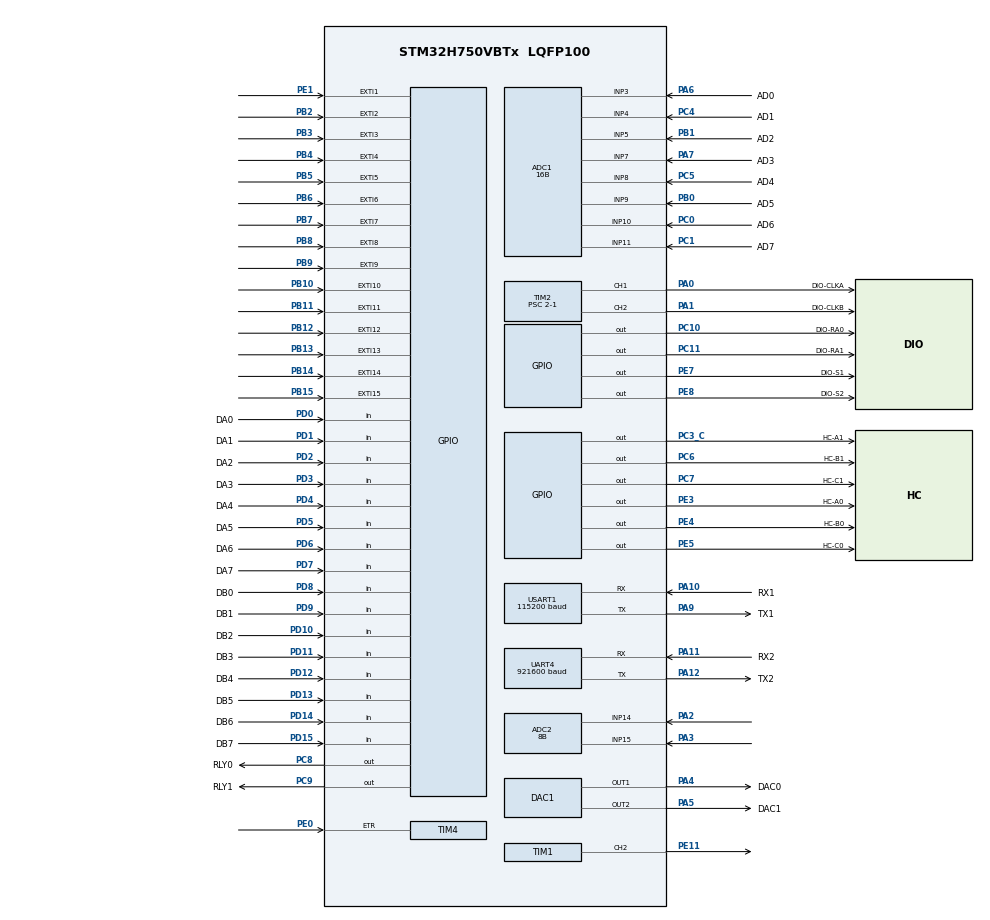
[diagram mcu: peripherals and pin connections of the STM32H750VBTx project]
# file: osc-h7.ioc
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ADC1.Channel-11\#ChannelRegularConversion=ADC_CHANNEL_3
ADC1.Channel-12\#ChannelRegularConversion=ADC_CHANNEL_4
ADC1.Channel-13\#ChannelRegularConversion=ADC_CHANNEL_5
ADC1.Channel-14\#ChannelRegularConversion=ADC_CHANNEL_7
ADC1.Channel-15\#ChannelRegularConversion=ADC_CHANNEL_8
ADC1.Channel-16\#ChannelRegularConversion=ADC_CHANNEL_9
ADC1.Channel-17\#ChannelRegularConversion=ADC_CHANNEL_10
ADC1.Channel-18\#ChannelRegularConversion=ADC_CHANNEL_11
ADC1.ClockPrescaler=ADC_CLOCK_ASYNC_DIV16
ADC1.ContinuousConvMode=DISABLE
ADC1.ConversionDataManagement=ADC_CONVERSIONDATA_DR
ADC1.DiscontinuousConvMode=ENABLE
ADC1.Mode=ADC_MODE_INDEPENDENT
ADC1.NbrOfConversion=8
ADC1.NbrOfConversionFlag=1
ADC1.OffsetNumber-11\#ChannelRegularConversion=ADC_OFFSET_NONE
ADC1.OffsetNumber-12\#ChannelRegularConversion=ADC_OFFSET_NONE
ADC1.OffsetNumber-13\#ChannelRegularConversion=ADC_OFFSET_NONE
ADC1.OffsetNumber-14\#ChannelRegularConversion=ADC_OFFSET_NONE
ADC1.OffsetNumber-15\#ChannelRegularConversion=ADC_OFFSET_NONE
ADC1.OffsetNumber-16\#ChannelRegularConversion=ADC_OFFSET_NONE
ADC1.OffsetNumber-17\#ChannelRegularConversion=ADC_OFFSET_NONE
ADC1.OffsetNumber-18\#ChannelRegularConversion=ADC_OFFSET_NONE
ADC1.OffsetSignedSaturation-11\#ChannelRegularConversion=DISABLE
ADC1.OffsetSignedSaturation-12\#ChannelRegularConversion=DISABLE
ADC1.OffsetSignedSaturation-13\#ChannelRegularConversion=DISABLE
ADC1.OffsetSignedSaturation-14\#ChannelRegularConversion=DISABLE
ADC1.OffsetSignedSaturation-15\#ChannelRegularConversion=DISABLE
ADC1.OffsetSignedSaturation-16\#ChannelRegularConversion=DISABLE
ADC1.OffsetSignedSaturation-17\#ChannelRegularConversion=DISABLE
ADC1.OffsetSignedSaturation-18\#ChannelRegularConversion=DISABLE
ADC1.Overrun=ADC_OVR_DATA_PRESERVED
ADC1.Rank-11\#ChannelRegularConversion=1
ADC1.Rank-12\#ChannelRegularConversion=2
ADC1.Rank-13\#ChannelRegularConversion=3
ADC1.Rank-14\#ChannelRegularConversion=4
ADC1.Rank-15\#ChannelRegularConversion=5
ADC1.Rank-16\#ChannelRegularConversion=6
ADC1.Rank-17\#ChannelRegularConversion=7
ADC1.Rank-18\#ChannelRegularConversion=8
ADC1.Resolution=ADC_RESOLUTION_16B
ADC1.SamplingTime-11\#ChannelRegularConversion=ADC_SAMPLETIME_387CYCLES_5
ADC1.SamplingTime-12\#ChannelRegularConversion=ADC_SAMPLETIME_387CYCLES_5
ADC1.SamplingTime-13\#ChannelRegularConversion=ADC_SAMPLETIME_387CYCLES_5
ADC1.SamplingTime-14\#ChannelRegularConversion=ADC_SAMPLETIME_1CYCLE_5
ADC1.SamplingTime-15\#ChannelRegularConversion=ADC_SAMPLETIME_1CYCLE_5
ADC1.SamplingTime-16\#ChannelRegularConversion=ADC_SAMPLETIME_1CYCLE_5
ADC1.SamplingTime-17\#ChannelRegularConversion=ADC_SAMPLETIME_1CYCLE_5
ADC1.SamplingTime-18\#ChannelRegularConversion=ADC_SAMPLETIME_1CYCLE_5
ADC1.master=1
ADC2.Channel-5\#ChannelRegularConversion=ADC_CHANNEL_14
ADC2.Channel-6\#ChannelRegularConversion=ADC_CHANNEL_15
ADC2.ClockPrescaler=ADC_CLOCK_ASYNC_DIV16
ADC2.ContinuousConvMode=ENABLE
ADC2.ConversionDataManagement=ADC_CONVERSIONDATA_DMA_CIRCULAR
ADC2.DiscontinuousConvMode=DISABLE
ADC2.NbrOfConversion=2
ADC2.NbrOfConversionFlag=1
ADC2.OffsetNumber-5\#ChannelRegularConversion=ADC_OFFSET_NONE
ADC2.OffsetNumber-6\#ChannelRegularConversion=ADC_OFFSET_NONE
ADC2.OffsetSignedSaturation-5\#ChannelRegularConversion=DISABLE
ADC2.OffsetSignedSaturation-6\#ChannelRegularConversion=DISABLE
ADC2.Overrun=ADC_OVR_DATA_OVERWRITTEN
ADC2.Rank-5\#ChannelRegularConversion=1
ADC2.Rank-6\#ChannelRegularConversion=2
ADC2.Resolution=ADC_RESOLUTION_8B
ADC2.SamplingTime-5\#ChannelRegularConversion=ADC_SAMPLETIME_1CYCLE_5
ADC2.SamplingTime-6\#ChannelRegularConversion=ADC_SAMPLETIME_1CYCLE_5
Bdma.BDMA_GENERATOR0.0.Direction=DMA_PERIPH_TO_MEMORY
Bdma.BDMA_GENERATOR0.0.EventEnable=DISABLE
Bdma.BDMA_GENERATOR0.0.Instance=BDMA_Channel0
Bdma.BDMA_GENERATOR0.0.MemDataAlignment=DMA_MDATAALIGN_BYTE
Bdma.BDMA_GENERATOR0.0.MemInc=DMA_MINC_ENABLE
Bdma.BDMA_GENERATOR0.0.Mode=DMA_NORMAL
Bdma.BDMA_GENERATOR0.0.PeriphDataAlignment=DMA_PDATAALIGN_BYTE
Bdma.BDMA_GENERATOR0.0.PeriphInc=DMA_PINC_DISABLE
Bdma.BDMA_GENERATOR0.0.Polarity=HAL_DMAMUX_REQ_GEN_RISING
Bdma.BDMA_GENERATOR0.0.Priority=DMA_PRIORITY_LOW
Bdma.BDMA_GENERATOR0.0.RequestNumber=1
Bdma.BDMA_GENERATOR0.0.SignalID=NONE
Bdma.BDMA_GENERATOR0.0.SyncEnable=DISABLE
Bdma.BDMA_GENERATOR0.0.SyncPolarity=HAL_DMAMUX_SYNC_NO_EVENT
Bdma.BDMA_GENERATOR0.0.SyncRequestNumber=1
Bdma.BDMA_GENERATOR0.0.SyncSignalID=NONE
Bdma.Request0=BDMA_GENERATOR0
Bdma.RequestsNb=1
DAC1.DAC_Channel-DAC_OUT1=DAC_CHANNEL_1
DAC1.DAC_Channel-DAC_OUT2=DAC_CHANNEL_2
Dma.ADC1.5.Direction=DMA_PERIPH_TO_MEMORY
Dma.ADC1.5.EventEnable=DISABLE
Dma.ADC1.5.FIFOMode=DMA_FIFOMODE_DISABLE
Dma.ADC1.5.Instance=DMA2_Stream2
Dma.ADC1.5.MemDataAlignment=DMA_MDATAALIGN_WORD
Dma.ADC1.5.MemInc=DMA_MINC_ENABLE
Dma.ADC1.5.Mode=DMA_CIRCULAR
Dma.ADC1.5.PeriphDataAlignment=DMA_PDATAALIGN_WORD
Dma.ADC1.5.PeriphInc=DMA_PINC_DISABLE
Dma.ADC1.5.Polarity=HAL_DMAMUX_REQ_GEN_RISING
Dma.ADC1.5.Priority=DMA_PRIORITY_LOW
Dma.ADC1.5.RequestNumber=1
Dma.ADC1.5.SignalID=NONE
Dma.ADC1.5.SyncEnable=DISABLE
Dma.ADC1.5.SyncPolarity=HAL_DMAMUX_SYNC_NO_EVENT
Dma.ADC1.5.SyncRequestNumber=1
Dma.ADC1.5.SyncSignalID=NONE
Dma.ADC2.0.Direction=DMA_PERIPH_TO_MEMORY
Dma.ADC2.0.EventEnable=DISABLE
Dma.ADC2.0.FIFOMode=DMA_FIFOMODE_ENABLE
Dma.ADC2.0.FIFOThreshold=DMA_FIFO_THRESHOLD_FULL
Dma.ADC2.0.Instance=DMA1_Stream0
Dma.ADC2.0.MemBurst=DMA_MBURST_SINGLE
Dma.ADC2.0.MemDataAlignment=DMA_MDATAALIGN_BYTE
Dma.ADC2.0.MemInc=DMA_MINC_ENABLE
Dma.ADC2.0.Mode=DMA_CIRCULAR
Dma.ADC2.0.PeriphBurst=DMA_PBURST_SINGLE
Dma.ADC2.0.PeriphDataAlignment=DMA_PDATAALIGN_BYTE
Dma.ADC2.0.PeriphInc=DMA_PINC_DISABLE
Dma.ADC2.0.Polarity=HAL_DMAMUX_REQ_GEN_RISING
Dma.ADC2.0.Priority=DMA_PRIORITY_LOW
Dma.ADC2.0.RequestNumber=1
Dma.ADC2.0.SignalID=NONE
Dma.ADC2.0.SyncEnable=DISABLE
Dma.ADC2.0.SyncPolarity=HAL_DMAMUX_SYNC_NO_EVENT
Dma.ADC2.0.SyncRequestNumber=1
Dma.ADC2.0.SyncSignalID=NONE
Dma.Request0=ADC2
Dma.Request1=TIM2_CH1
Dma.Request2=TIM2_UP
Dma.Request3=USART1_RX
Dma.Request4=USART1_TX
Dma.Request5=ADC1
Dma.Request6=TIM1_CH2
Dma.Request7=TIM1_CH4
Dma.Request8=TIM1_CH3
Dma.TIM1_CH2.6.Direction=DMA_PERIPH_TO_MEMORY
Dma.TIM1_CH2.6.EventEnable=DISABLE
Dma.TIM1_CH2.6.FIFOMode=DMA_FIFOMODE_DISABLE
Dma.TIM1_CH2.6.Instance=DMA1_Stream2
Dma.TIM1_CH2.6.MemDataAlignment=DMA_MDATAALIGN_HALFWORD
Dma.TIM1_CH2.6.MemInc=DMA_MINC_ENABLE
Dma.TIM1_CH2.6.Mode=DMA_NORMAL
Dma.TIM1_CH2.6.PeriphDataAlignment=DMA_PDATAALIGN_HALFWORD
Dma.TIM1_CH2.6.PeriphInc=DMA_PINC_DISABLE
Dma.TIM1_CH2.6.Polarity=HAL_DMAMUX_REQ_GEN_RISING
Dma.TIM1_CH2.6.Priority=DMA_PRIORITY_LOW
Dma.TIM1_CH2.6.RequestNumber=1
Dma.TIM1_CH2.6.SignalID=NONE
Dma.TIM1_CH2.6.SyncEnable=DISABLE
Dma.TIM1_CH2.6.SyncPolarity=HAL_DMAMUX_SYNC_NO_EVENT
Dma.TIM1_CH2.6.SyncRequestNumber=1
Dma.TIM1_CH2.6.SyncSignalID=NONE
Dma.TIM1_CH3.8.Direction=DMA_PERIPH_TO_MEMORY
Dma.TIM1_CH3.8.EventEnable=DISABLE
Dma.TIM1_CH3.8.FIFOMode=DMA_FIFOMODE_DISABLE
Dma.TIM1_CH3.8.Instance=DMA1_Stream3
Dma.TIM1_CH3.8.MemDataAlignment=DMA_MDATAALIGN_HALFWORD
Dma.TIM1_CH3.8.MemInc=DMA_MINC_ENABLE
Dma.TIM1_CH3.8.Mode=DMA_NORMAL
Dma.TIM1_CH3.8.PeriphDataAlignment=DMA_PDATAALIGN_HALFWORD
Dma.TIM1_CH3.8.PeriphInc=DMA_PINC_DISABLE
Dma.TIM1_CH3.8.Polarity=HAL_DMAMUX_REQ_GEN_RISING
Dma.TIM1_CH3.8.Priority=DMA_PRIORITY_LOW
Dma.TIM1_CH3.8.RequestNumber=1
Dma.TIM1_CH3.8.SignalID=NONE
Dma.TIM1_CH3.8.SyncEnable=DISABLE
Dma.TIM1_CH3.8.SyncPolarity=HAL_DMAMUX_SYNC_NO_EVENT
Dma.TIM1_CH3.8.SyncRequestNumber=1
Dma.TIM1_CH3.8.SyncSignalID=NONE
Dma.TIM1_CH4.7.Direction=DMA_PERIPH_TO_MEMORY
Dma.TIM1_CH4.7.EventEnable=DISABLE
Dma.TIM1_CH4.7.FIFOMode=DMA_FIFOMODE_DISABLE
Dma.TIM1_CH4.7.Instance=DMA1_Stream4
Dma.TIM1_CH4.7.MemDataAlignment=DMA_MDATAALIGN_HALFWORD
Dma.TIM1_CH4.7.MemInc=DMA_MINC_ENABLE
Dma.TIM1_CH4.7.Mode=DMA_NORMAL
Dma.TIM1_CH4.7.PeriphDataAlignment=DMA_PDATAALIGN_HALFWORD
Dma.TIM1_CH4.7.PeriphInc=DMA_PINC_DISABLE
Dma.TIM1_CH4.7.Polarity=HAL_DMAMUX_REQ_GEN_RISING
Dma.TIM1_CH4.7.Priority=DMA_PRIORITY_LOW
Dma.TIM1_CH4.7.RequestNumber=1
Dma.TIM1_CH4.7.SignalID=NONE
Dma.TIM1_CH4.7.SyncEnable=DISABLE
Dma.TIM1_CH4.7.SyncPolarity=HAL_DMAMUX_SYNC_NO_EVENT
Dma.TIM1_CH4.7.SyncRequestNumber=1
Dma.TIM1_CH4.7.SyncSignalID=NONE
Dma.TIM2_CH1.1.Direction=DMA_PERIPH_TO_MEMORY
Dma.TIM2_CH1.1.EventEnable=DISABLE
Dma.TIM2_CH1.1.FIFOMode=DMA_FIFOMODE_DISABLE
Dma.TIM2_CH1.1.Instance=DMA2_Stream0
Dma.TIM2_CH1.1.MemDataAlignment=DMA_MDATAALIGN_HALFWORD
Dma.TIM2_CH1.1.MemInc=DMA_MINC_ENABLE
Dma.TIM2_CH1.1.Mode=DMA_NORMAL
Dma.TIM2_CH1.1.PeriphDataAlignment=DMA_PDATAALIGN_HALFWORD
Dma.TIM2_CH1.1.PeriphInc=DMA_PINC_DISABLE
Dma.TIM2_CH1.1.Polarity=HAL_DMAMUX_REQ_GEN_RISING
Dma.TIM2_CH1.1.Priority=DMA_PRIORITY_LOW
Dma.TIM2_CH1.1.RequestNumber=1
Dma.TIM2_CH1.1.SignalID=NONE
Dma.TIM2_CH1.1.SyncEnable=DISABLE
Dma.TIM2_CH1.1.SyncPolarity=HAL_DMAMUX_SYNC_NO_EVENT
Dma.TIM2_CH1.1.SyncRequestNumber=1
Dma.TIM2_CH1.1.SyncSignalID=NONE
Dma.TIM2_UP.2.Direction=DMA_PERIPH_TO_MEMORY
Dma.TIM2_UP.2.EventEnable=DISABLE
Dma.TIM2_UP.2.FIFOMode=DMA_FIFOMODE_DISABLE
Dma.TIM2_UP.2.Instance=DMA2_Stream4
Dma.TIM2_UP.2.MemDataAlignment=DMA_MDATAALIGN_WORD
Dma.TIM2_UP.2.MemInc=DMA_MINC_ENABLE
Dma.TIM2_UP.2.Mode=DMA_NORMAL
Dma.TIM2_UP.2.PeriphDataAlignment=DMA_PDATAALIGN_WORD
Dma.TIM2_UP.2.PeriphInc=DMA_PINC_DISABLE
Dma.TIM2_UP.2.Polarity=HAL_DMAMUX_REQ_GEN_RISING
Dma.TIM2_UP.2.Priority=DMA_PRIORITY_LOW
Dma.TIM2_UP.2.RequestNumber=1
Dma.TIM2_UP.2.SignalID=NONE
Dma.TIM2_UP.2.SyncEnable=DISABLE
Dma.TIM2_UP.2.SyncPolarity=HAL_DMAMUX_SYNC_NO_EVENT
Dma.TIM2_UP.2.SyncRequestNumber=1
Dma.TIM2_UP.2.SyncSignalID=NONE
Dma.USART1_RX.3.Direction=DMA_PERIPH_TO_MEMORY
Dma.USART1_RX.3.EventEnable=DISABLE
Dma.USART1_RX.3.FIFOMode=DMA_FIFOMODE_DISABLE
Dma.USART1_RX.3.Instance=DMA1_Stream5
Dma.USART1_RX.3.MemDataAlignment=DMA_MDATAALIGN_HALFWORD
Dma.USART1_RX.3.MemInc=DMA_MINC_ENABLE
Dma.USART1_RX.3.Mode=DMA_NORMAL
Dma.USART1_RX.3.PeriphDataAlignment=DMA_PDATAALIGN_HALFWORD
Dma.USART1_RX.3.PeriphInc=DMA_PINC_DISABLE
Dma.USART1_RX.3.Polarity=HAL_DMAMUX_REQ_GEN_RISING
Dma.USART1_RX.3.Priority=DMA_PRIORITY_LOW
Dma.USART1_RX.3.RequestNumber=1
Dma.USART1_RX.3.SignalID=NONE
Dma.USART1_RX.3.SyncEnable=DISABLE
Dma.USART1_RX.3.SyncPolarity=HAL_DMAMUX_SYNC_NO_EVENT
Dma.USART1_RX.3.SyncRequestNumber=1
Dma.USART1_RX.3.SyncSignalID=NONE
Dma.USART1_TX.4.Direction=DMA_MEMORY_TO_PERIPH
Dma.USART1_TX.4.EventEnable=DISABLE
Dma.USART1_TX.4.FIFOMode=DMA_FIFOMODE_DISABLE
Dma.USART1_TX.4.Instance=DMA1_Stream6
Dma.USART1_TX.4.MemDataAlignment=DMA_MDATAALIGN_HALFWORD
Dma.USART1_TX.4.MemInc=DMA_MINC_ENABLE
Dma.USART1_TX.4.Mode=DMA_NORMAL
Dma.USART1_TX.4.PeriphDataAlignment=DMA_PDATAALIGN_HALFWORD
Dma.USART1_TX.4.PeriphInc=DMA_PINC_DISABLE
Dma.USART1_TX.4.Polarity=HAL_DMAMUX_REQ_GEN_RISING
Dma.USART1_TX.4.Priority=DMA_PRIORITY_LOW
Dma.USART1_TX.4.RequestNumber=1
Dma.USART1_TX.4.SignalID=NONE
Dma.USART1_TX.4.SyncEnable=DISABLE
Dma.USART1_TX.4.SyncPolarity=HAL_DMAMUX_SYNC_NO_EVENT
Dma.USART1_TX.4.SyncRequestNumber=1
Dma.USART1_TX.4.SyncSignalID=NONE
Mcu.Family=STM32H7
Mcu.Name=STM32H750VBTx
Mcu.Package=LQFP100
NVIC.DMA1_Stream0_IRQn=true\:0\:0\:false\:false\:true\:false\:true\:true
NVIC.DMA1_Stream2_IRQn=true\:0\:0\:false\:false\:true\:false\:true\:true
NVIC.DMA1_Stream3_IRQn=true\:0\:0\:false\:false\:true\:false\:true\:true
NVIC.DMA1_Stream4_IRQn=true\:0\:0\:false\:false\:true\:false\:true\:true
NVIC.DMA1_Stream5_IRQn=true\:0\:0\:false\:false\:true\:false\:true\:true
NVIC.DMA1_Stream6_IRQn=true\:0\:0\:false\:false\:true\:false\:true\:true
NVIC.DMA2_Stream0_IRQn=true\:0\:0\:false\:false\:true\:false\:true\:true
NVIC.DMA2_Stream2_IRQn=true\:0\:0\:false\:false\:true\:false\:true\:true
NVIC.DMA2_Stream4_IRQn=true\:0\:0\:false\:false\:true\:false\:true\:true
NVIC.EXTI15_10_IRQn=true\:2\:1\:true\:false\:true\:true\:true\:true
NVIC.EXTI1_IRQn=true\:2\:1\:true\:false\:true\:true\:true\:true
NVIC.EXTI2_IRQn=true\:2\:1\:true\:false\:true\:true\:true\:true
NVIC.EXTI3_IRQn=true\:2\:1\:true\:false\:true\:true\:true\:true
NVIC.EXTI4_IRQn=true\:2\:1\:true\:false\:true\:true\:true\:true
NVIC.EXTI9_5_IRQn=true\:2\:1\:true\:false\:true\:true\:true\:true
NVIC.PriorityGroup=NVIC_PRIORITYGROUP_3
NVIC.TIM3_IRQn=true\:2\:1\:true\:false\:true\:true\:true\:true
NVIC.TIM5_IRQn=true\:4\:0\:true\:false\:true\:true\:true\:true
NVIC.USART1_IRQn=true\:0\:0\:false\:false\:true\:true\:true\:true
PA0.GPIO_Label=DIO-CLKA
PA0.PinAttribute=Free
PA0.Signal=S_TIM2_CH1_ETR
PA1.GPIO_Label=DIO-CLKB
PA1.Signal=S_TIM2_CH2
PA10.GPIO_Label=RX1
PA10.Mode=Asynchronous
PA10.Signal=USART1_RX
PA11.GPIO_Label=RX2
PA11.Mode=Asynchronous
PA11.Signal=UART4_RX
PA12.GPIO_Label=TX2
PA12.Mode=Asynchronous
PA12.Signal=UART4_TX
PA2.Signal=ADCx_INP14
PA3.Signal=ADCx_INP15
PA4.GPIO_Label=DAC0
PA4.Signal=COMP_DAC11_group
PA5.GPIO_Label=DAC1
PA5.Signal=COMP_DAC12_group
PA6.GPIO_Label=AD0
PA6.Signal=ADCx_INP3
PA7.GPIO_Label=AD3
PA7.Signal=ADCx_INP7
PA9.GPIO_Label=TX1
PA9.Mode=Asynchronous
PA9.Signal=USART1_TX
PB0.GPIO_Label=AD5
PB0.Signal=ADCx_INP9
PB1.GPIO_Label=AD2
PB1.Signal=ADCx_INP5
PB10.GPIO_ModeDefaultEXTI=GPIO_MODE_IT_FALLING
PB10.GPIO_PuPd=GPIO_PULLUP
PB10.Signal=GPXTI10
PB11.GPIO_ModeDefaultEXTI=GPIO_MODE_IT_FALLING
PB11.GPIO_PuPd=GPIO_PULLUP
PB11.Signal=GPXTI11
PB12.GPIO_ModeDefaultEXTI=GPIO_MODE_IT_FALLING
PB12.GPIO_PuPd=GPIO_PULLUP
PB12.Signal=GPXTI12
PB13.GPIO_ModeDefaultEXTI=GPIO_MODE_IT_FALLING
PB13.GPIO_PuPd=GPIO_PULLUP
PB13.Signal=GPXTI13
PB14.GPIO_ModeDefaultEXTI=GPIO_MODE_IT_FALLING
PB14.GPIO_PuPd=GPIO_PULLUP
PB14.Signal=GPXTI14
PB15.GPIO_ModeDefaultEXTI=GPIO_MODE_IT_FALLING
PB15.GPIO_PuPd=GPIO_PULLUP
PB15.Signal=GPXTI15
PB2.GPIO_ModeDefaultEXTI=GPIO_MODE_IT_FALLING
PB2.GPIO_PuPd=GPIO_PULLUP
PB2.Signal=GPXTI2
PB3\ (JTDO/TRACESWO).GPIO_ModeDefaultEXTI=GPIO_MODE_IT_FALLING
PB3\ (JTDO/TRACESWO).GPIO_PuPd=GPIO_PULLUP
PB3\ (JTDO/TRACESWO).Signal=GPXTI3
PB4\ (NJTRST).GPIO_ModeDefaultEXTI=GPIO_MODE_IT_FALLING
PB4\ (NJTRST).GPIO_PuPd=GPIO_PULLUP
PB4\ (NJTRST).Signal=GPXTI4
PB5.GPIO_ModeDefaultEXTI=GPIO_MODE_IT_FALLING
PB5.GPIO_PuPd=GPIO_PULLUP
PB5.PinAttribute=Free
PB5.Signal=GPXTI5
PB6.GPIO_ModeDefaultEXTI=GPIO_MODE_IT_FALLING
PB6.GPIO_PuPd=GPIO_PULLUP
PB6.Signal=GPXTI6
PB7.GPIO_ModeDefaultEXTI=GPIO_MODE_IT_FALLING
PB7.GPIO_PuPd=GPIO_PULLUP
PB7.Signal=GPXTI7
PB8.GPIO_ModeDefaultEXTI=GPIO_MODE_IT_FALLING
PB8.GPIO_PuPd=GPIO_PULLUP
PB8.Signal=GPXTI8
PB9.GPIO_ModeDefaultEXTI=GPIO_MODE_IT_FALLING
PB9.GPIO_PuPd=GPIO_PULLUP
PB9.Signal=GPXTI9
PC0.GPIO_Label=AD6
PC0.Signal=ADCx_INP10
PC1.GPIO_Label=AD7
PC1.Signal=ADCx_INP11
PC10.GPIO_Label=DIO-RA0
PC10.GPIO_ModeDefaultOutputPP=GPIO_MODE_OUTPUT_PP
PC10.PinAttribute=Free
PC10.Signal=GPIO_Output
PC11.GPIO_Label=DIO-RA1
PC11.GPIO_ModeDefaultOutputPP=GPIO_MODE_OUTPUT_PP
PC11.PinAttribute=Free
PC11.Signal=GPIO_Output
PC3_C.GPIO_Label=HC-A1
PC3_C.GPIO_ModeDefaultOutputPP=GPIO_MODE_OUTPUT_PP
PC3_C.PinAttribute=Free
PC3_C.Signal=GPIO_Output
PC4.GPIO_Label=AD1
PC4.Signal=ADCx_INP4
PC5.GPIO_Label=AD4
PC5.Signal=ADCx_INP8
PC6.GPIO_Label=HC-B1
PC6.GPIO_ModeDefaultOutputPP=GPIO_MODE_OUTPUT_PP
PC6.Signal=GPIO_Output
PC7.GPIO_Label=HC-C1
PC7.GPIO_ModeDefaultOutputPP=GPIO_MODE_OUTPUT_PP
PC7.Signal=GPIO_Output
PC8.GPIO_Label=RLY0
PC8.GPIO_ModeDefaultOutputPP=GPIO_MODE_OUTPUT_PP
PC8.Signal=GPIO_Output
PC9.GPIO_Label=RLY1
PC9.GPIO_ModeDefaultOutputPP=GPIO_MODE_OUTPUT_PP
PC9.Signal=GPIO_Output
PD0.GPIO_Label=DA0
PD0.GPIO_PuPd=GPIO_PULLDOWN
PD0.PinAttribute=Free
PD0.Signal=GPIO_Input
PD1.GPIO_Label=DA1
PD1.GPIO_PuPd=GPIO_PULLDOWN
PD1.PinAttribute=Free
PD1.Signal=GPIO_Input
PD10.GPIO_Label=DB2
PD10.GPIO_PuPd=GPIO_PULLDOWN
PD10.Signal=GPIO_Input
PD11.GPIO_Label=DB3
PD11.GPIO_Mode=GPIO_MODE_INPUT
PD11.GPIO_PuPd=GPIO_PULLDOWN
PD11.Signal=GPIO_Input
PD12.GPIO_Label=DB4
PD12.GPIO_Mode=GPIO_MODE_INPUT
PD12.GPIO_PuPd=GPIO_PULLDOWN
PD12.Signal=GPIO_Input
PD13.GPIO_Label=DB5
PD13.GPIO_Mode=GPIO_MODE_INPUT
PD13.GPIO_PuPd=GPIO_PULLDOWN
PD13.Signal=GPIO_Input
PD14.GPIO_Label=DB6
PD14.GPIO_Mode=GPIO_MODE_INPUT
PD14.GPIO_PuPd=GPIO_PULLDOWN
PD14.Signal=GPIO_Input
PD15.GPIO_Label=DB7
PD15.GPIO_Mode=GPIO_MODE_INPUT
PD15.GPIO_PuPd=GPIO_PULLDOWN
PD15.Signal=GPIO_Input
PD2.GPIO_Label=DA2
PD2.GPIO_PuPd=GPIO_PULLDOWN
PD2.PinAttribute=Free
PD2.Signal=GPIO_Input
PD3.GPIO_Label=DA3
PD3.GPIO_PuPd=GPIO_PULLUP
PD3.PinAttribute=Free
PD3.Signal=GPIO_Input
PD4.GPIO_Label=DA4
PD4.GPIO_PuPd=GPIO_PULLDOWN
PD4.PinAttribute=Free
PD4.Signal=GPIO_Input
PD5.GPIO_Label=DA5
PD5.GPIO_PuPd=GPIO_PULLDOWN
PD5.PinAttribute=Free
PD5.Signal=GPIO_Input
PD6.GPIO_Label=DA6
PD6.GPIO_PuPd=GPIO_PULLDOWN
PD6.PinAttribute=Free
PD6.Signal=GPIO_Input
PD7.GPIO_Label=DA7
PD7.GPIO_PuPd=GPIO_PULLUP
PD7.Signal=GPIO_Input
PD8.GPIO_Label=DB0
PD8.GPIO_PuPd=GPIO_PULLDOWN
PD8.Signal=GPIO_Input
PD9.GPIO_Label=DB1
PD9.GPIO_PuPd=GPIO_PULLDOWN
PD9.Signal=GPIO_Input
PE0.Signal=S_TIM4_ETR
PE1.GPIO_ModeDefaultEXTI=GPIO_MODE_IT_FALLING
PE1.GPIO_PuPd=GPIO_PULLUP
PE1.PinAttribute=Free
PE1.Signal=GPXTI1
PE11.Signal=S_TIM1_CH2
PE3.GPIO_Label=HC-A0
PE3.PinAttribute=Free
PE3.Signal=GPIO_Output
PE4.GPIO_Label=HC-B0
PE4.PinAttribute=Free
PE4.Signal=GPIO_Output
PE5.GPIO_Label=HC-C0
PE5.PinAttribute=Free
PE5.Signal=GPIO_Output
PE7.GPIO_Label=DIO-S1
PE7.Signal=GPIO_Output
PE8.GPIO_Label=DIO-S2
PE8.Signal=GPIO_Output
PH0-OSC_IN\ (PH0).Mode=HSE-External-Oscillator
PH0-OSC_IN\ (PH0).PinAttribute=Free
PH0-OSC_IN\ (PH0).Signal=RCC_OSC_IN
PH1-OSC_OUT\ (PH1).Mode=HSE-External-Oscillator
PH1-OSC_OUT\ (PH1).Signal=RCC_OSC_OUT
ProjectManager.HeapSize=0x200
ProjectManager.StackSize=0x400
ProjectManager.TargetToolchain=MDK-ARM V5.32
RCC.ADCFreq_Value=75000000
RCC.APB1Freq_Value=100000000
RCC.APB2Freq_Value=100000000
RCC.APB3Freq_Value=100000000
RCC.APB4Freq_Value=100000000
RCC.CortexFreq_Value=400000000
RCC.D1PPRE=RCC_APB3_DIV2
RCC.D2PPRE1=RCC_APB1_DIV2
RCC.D2PPRE2=RCC_APB2_DIV2
RCC.D3PPRE=RCC_APB4_DIV2
RCC.DIVM1=4
RCC.DIVM2=4
RCC.DIVN1=50
RCC.DIVN2=9
RCC.FLatency-AdvancedSettings=FLASH_LATENCY_4
RCC.HCLKFreq_Value=200000000
RCC.HPRE=RCC_HCLK_DIV2
RCC.PLL1_VCI_Range-AdvancedSettings=RCC_PLL1VCIRANGE_1
RCC.PLL2FRACN=3072
RCC.PLL2_VCI_Range-AdvancedSettings=RCC_PLL2VCIRANGE_2
RCC.PLL3FRACN=0
RCC.PLL3_VCI_Range-AdvancedSettings=RCC_PLL3VCIRANGE_0
RCC.PLL3_VCO_SEL-AdvancedSettings=RCC_PLL3VCOMEDIUM
RCC.PLLFRACN=0
RCC.SYSCLKFreq_VALUE=400000000
RCC.SYSCLKSource=RCC_SYSCLKSOURCE_PLLCLK
RCC.USART16CLockSelection=RCC_USART16CLKSOURCE_PLL2
RCC.USART234578CLockSelection=RCC_USART234578CLKSOURCE_PLL2
RCC.USBFreq_Value=400000000
SH.ADCx_INP10.0=ADC1_INP10,IN10-Single-Ended
SH.ADCx_INP11.0=ADC1_INP11,IN11-Single-Ended
SH.ADCx_INP14.0=ADC2_INP14,IN14-Single-Ended
SH.ADCx_INP15.0=ADC2_INP15,IN15-Single-Ended
SH.ADCx_INP3.0=ADC1_INP3,IN3-Single-Ended
SH.ADCx_INP4.0=ADC1_INP4,IN4-Single-Ended
SH.ADCx_INP5.0=ADC1_INP5,IN5-Single-Ended
SH.ADCx_INP7.0=ADC1_INP7,IN7-Single-Ended
SH.ADCx_INP8.0=ADC1_INP8,IN8-Single-Ended
SH.ADCx_INP9.0=ADC1_INP9,IN9-Single-Ended
SH.COMP_DAC11_group.0=DAC1_OUT1,DAC_OUT1
SH.COMP_DAC12_group.0=DAC1_OUT2,DAC_OUT2
SH.S_TIM1_CH2.0=TIM1_CH2,PWM Generation2 CH2
SH.S_TIM2_CH1_ETR.0=TIM2_CH1,PWM Generation1 CH1
SH.S_TIM2_CH2.0=TIM2_CH2,PWM Generation2 CH2
SH.S_TIM4_ETR.0=TIM4_ETR,ClockSourceETR_Mode2
TIM1.Channel-PWM\ Generation2\ CH2=TIM_CHANNEL_2
TIM1.Channel-PWM\ Generation3\ No\ Output=TIM_CHANNEL_3
TIM1.Channel-PWM\ Generation4\ No\ Output=TIM_CHANNEL_4
TIM1.OCPolarity_2=TIM_OCPOLARITY_HIGH
TIM1.Period=4-1
TIM1.Prescaler=2-1
TIM1.Pulse-PWM\ Generation2\ CH2=1
TIM1.TIM_MasterOutputTrigger=TIM_TRGO_ENABLE
TIM1.TIM_MasterOutputTrigger2=TIM_TRGO2_ENABLE
TIM1.TIM_MasterSlaveMode=TIM_MASTERSLAVEMODE_ENABLE
TIM2.AutoReloadPreload=TIM_AUTORELOAD_PRELOAD_ENABLE
TIM2.Channel-PWM\ Generation1\ CH1=TIM_CHANNEL_1
TIM2.Channel-PWM\ Generation2\ CH2=TIM_CHANNEL_2
TIM2.Period=2-1
TIM2.Prescaler=2-1
TIM2.Pulse-PWM\ Generation1\ CH1=1
TIM2.Pulse-PWM\ Generation2\ CH2=1
TIM2.TIM_MasterOutputTrigger=TIM_TRGO_ENABLE
TIM2.TIM_MasterSlaveMode=TIM_MASTERSLAVEMODE_ENABLE
TIM3.Period=2000-1
TIM3.Prescaler=20000-1
TIM4.Period=50000-1
TIM5.Period=50000-1
TIM5.Prescaler=2000-1
UART4.BaudRate=921600
USART1.BaudRate=115200
USART1.VirtualMode-Asynchronous=VM_ASYNC
VP_TIM1_VS_NoETR.Mode=ClockSourceETR_Mode2_ADC_Remap_TIM1
VP_TIM1_VS_no_output3.Mode=PWM Generation3 No Output
VP_TIM1_VS_no_output4.Mode=PWM Generation4 No Output
VP_TIM2_VS_ClockSourceINT.Mode=Internal
VP_TIM3_VS_ClockSourceINT.Mode=Internal
VP_TIM5_VS_ClockSourceINT.Mode=Internal
VP_VREFBUF_V_VREFBUF.Mode=ExternalMode
board=custom

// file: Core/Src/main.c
/* USER CODE BEGIN Header */
/**
  ******************************************************************************
  * @file           : main.c
  * @brief          : Main program body
  ******************************************************************************
  * @attention
  *
  * Copyright (c) 2024 STMicroelectronics.
  * All rights reserved.
  *
  * This software is licensed under terms that can be found in the LICENSE file
  * in the root directory of this software component.
  * If no LICENSE file comes with this software, it is provided AS-IS.
  *
  ******************************************************************************
  */
/* USER CODE END Header */
#include "main.h"
#include "adc.h"
#include "bdma.h"
#include "dac.h"
#include "dma.h"
#include "tim.h"
#include "usart.h"
#include "gpio.h"

/* USER CODE BEGIN Includes */
#include "stdio.h"
#include "osc.h"
#include "key.h"
#include "filter.h"
/* USER CODE END Includes */

/* USER CODE BEGIN PV */
uint8_t TxMsg[] = "\r\n*****USART communication based on DMA*****\r\n";
/* USER CODE END PV */

void SystemClock_Config(void);
void PeriphCommonClock_Config(void);
/* USER CODE BEGIN PFP */

int fputc(int ch, FILE* file)
{
    UART4->TDR = ch & 0xFF;

    while((UART4->ISR & UART_FLAG_TC) == RESET);

    return ch;
}

/* USER CODE END PFP */

int main(void)
{

  /* MCU Configuration--------------------------------------------------------*/

  /* Reset of all peripherals, Initializes the Flash interface and the Systick. */
  HAL_Init();

  /* Configure the system clock */
  SystemClock_Config();

/* Configure the peripherals common clocks */
  PeriphCommonClock_Config();

  /* Initialize all configured peripherals */
  MX_GPIO_Init();
  MX_DMA_Init();
  MX_BDMA_Init();
  MX_TIM3_Init();
  MX_USART1_UART_Init();
  MX_DAC1_Init();
  MX_ADC1_Init();
  MX_UART4_Init();
  MX_ADC2_Init();
  MX_TIM1_Init();
  MX_TIM2_Init();
  MX_TIM4_Init();
  MX_TIM5_Init();
  /* USER CODE BEGIN 2 */

	Init_Osc();

  /* USER CODE END 2 */

  /* Infinite loop */
  while (1)
  {

    /* USER CODE BEGIN 3 */
	//HAL_Delay(1000);

		//ADC+DMA
//			printf("%d",flag);
//			if(flag==1)
//			{
//				flag=0;
//			for(int i=0;i<10;i++)
//			printf("data%d=%d\r\n",i,data[i]);
//			}

//		if(flag==1)
//		{
//			flag=0;
//			printf("result:");
//			for(int j=0;j<1400;j++)
//			{
//					ad1[j]=ADC_Value[2*j];
//					if(ad1[j]>255) ad1[j]=255;
//			}
//			for(int j=0;j<1400;j++)
//			{
//					ad2[j]=ADC_Value[2*j+1];
//					if(ad2[j]>255) ad2[j]=255;
//			}
//			for(int j=0;j<50;j++)
//			{
//				printf("ad1=%d,ad2=%d\r\n",ad1[j],ad2[j]);
//			}
//		}
  }
  /* USER CODE END 3 */
}

void SystemClock_Config(void)
{
  RCC_OscInitTypeDef RCC_OscInitStruct = {0};
  RCC_ClkInitTypeDef RCC_ClkInitStruct = {0};

  /** Supply configuration update enable
  */
  HAL_PWREx_ConfigSupply(PWR_LDO_SUPPLY);

  /** Configure the main internal regulator output voltage
  */
  __HAL_PWR_VOLTAGESCALING_CONFIG(PWR_REGULATOR_VOLTAGE_SCALE1);

  while(!__HAL_PWR_GET_FLAG(PWR_FLAG_VOSRDY)) {}

  /** Initializes the RCC Oscillators according to the specified parameters
  * in the RCC_OscInitTypeDef structure.
  */
  RCC_OscInitStruct.OscillatorType = RCC_OSCILLATORTYPE_HSI;
  RCC_OscInitStruct.HSIState = RCC_HSI_DIV1;
  RCC_OscInitStruct.HSICalibrationValue = RCC_HSICALIBRATION_DEFAULT;
  RCC_OscInitStruct.PLL.PLLState = RCC_PLL_ON;
  RCC_OscInitStruct.PLL.PLLSource = RCC_PLLSOURCE_HSI;
  RCC_OscInitStruct.PLL.PLLM = 4;
  RCC_OscInitStruct.PLL.PLLN = 50;
  RCC_OscInitStruct.PLL.PLLP = 2;
  RCC_OscInitStruct.PLL.PLLQ = 2;
  RCC_OscInitStruct.PLL.PLLR = 2;
  RCC_OscInitStruct.PLL.PLLRGE = RCC_PLL1VCIRANGE_3;
  RCC_OscInitStruct.PLL.PLLVCOSEL = RCC_PLL1VCOWIDE;
  RCC_OscInitStruct.PLL.PLLFRACN = 0;
  if (HAL_RCC_OscConfig(&RCC_OscInitStruct) != HAL_OK)
  {
    Error_Handler();
  }

  /** Initializes the CPU, AHB and APB buses clocks
  */
  RCC_ClkInitStruct.ClockType = RCC_CLOCKTYPE_HCLK|RCC_CLOCKTYPE_SYSCLK
                              |RCC_CLOCKTYPE_PCLK1|RCC_CLOCKTYPE_PCLK2
                              |RCC_CLOCKTYPE_D3PCLK1|RCC_CLOCKTYPE_D1PCLK1;
  RCC_ClkInitStruct.SYSCLKSource = RCC_SYSCLKSOURCE_PLLCLK;
  RCC_ClkInitStruct.SYSCLKDivider = RCC_SYSCLK_DIV1;
  RCC_ClkInitStruct.AHBCLKDivider = RCC_HCLK_DIV2;
  RCC_ClkInitStruct.APB3CLKDivider = RCC_APB3_DIV2;
  RCC_ClkInitStruct.APB1CLKDivider = RCC_APB1_DIV2;
  RCC_ClkInitStruct.APB2CLKDivider = RCC_APB2_DIV2;
  RCC_ClkInitStruct.APB4CLKDivider = RCC_APB4_DIV2;

  if (HAL_RCC_ClockConfig(&RCC_ClkInitStruct, FLASH_LATENCY_2) != HAL_OK)
  {
    Error_Handler();
  }
}

void PeriphCommonClock_Config(void)
{
  RCC_PeriphCLKInitTypeDef PeriphClkInitStruct = {0};

  /** Initializes the peripherals clock
  */
  PeriphClkInitStruct.PeriphClockSelection = RCC_PERIPHCLK_ADC|RCC_PERIPHCLK_USART1
                              |RCC_PERIPHCLK_UART4;
  PeriphClkInitStruct.PLL2.PLL2M = 4;
  PeriphClkInitStruct.PLL2.PLL2N = 9;
  PeriphClkInitStruct.PLL2.PLL2P = 2;
  PeriphClkInitStruct.PLL2.PLL2Q = 2;
  PeriphClkInitStruct.PLL2.PLL2R = 2;
  PeriphClkInitStruct.PLL2.PLL2RGE = RCC_PLL2VCIRANGE_3;
  PeriphClkInitStruct.PLL2.PLL2VCOSEL = RCC_PLL2VCOMEDIUM;
  PeriphClkInitStruct.PLL2.PLL2FRACN = 3072;
  PeriphClkInitStruct.Usart234578ClockSelection = RCC_USART234578CLKSOURCE_PLL2;
  PeriphClkInitStruct.Usart16ClockSelection = RCC_USART16CLKSOURCE_PLL2;
  PeriphClkInitStruct.AdcClockSelection = RCC_ADCCLKSOURCE_PLL2;
  if (HAL_RCCEx_PeriphCLKConfig(&PeriphClkInitStruct) != HAL_OK)
  {
    Error_Handler();
  }
}

void Error_Handler(void)
{
  __disable_irq();
  while (1)
  {
  }
}
